# AT32UC3B1128 device description
Architecture: AVR32_UC3; Family: AVR UC3
Registers are 32-bit, read-write, reset 0x0 unless marked. A register's access mark holds for its fields unless they carry their own. Offsets are from the block's base; [hi:lo] are bit positions; {n}, {i} and the like mark numbered series; 'fields as' and 'values as' point back to an identical list.

## INTC — Interrupt Controller
Instances: INTC 0xFFFF0800
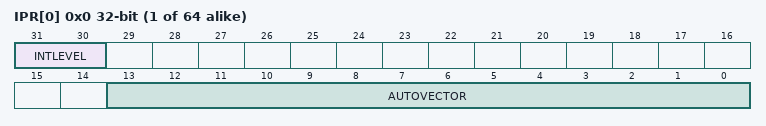
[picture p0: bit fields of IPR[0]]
{0x0+4i} IPR[{i}] (i=0..63) — Interrupt Priority Register
  [31:30] INTLEVEL — Interrupt Level
    {v}=INT{v} (v=0..3)
  [13:0] AUTOVECTOR — Handler offset
{0x100+4i} IRR[{i}] (i=0..63) ro — Interrupt Request Register
{0x200+4i} ICR[{i}] (i=0..3) ro — Interrupt Cause Register
  [5:0] CAUSE — Cause Group Number

## ADC — Analog to Digital Converter
Instances: ADC 0xffff3c00
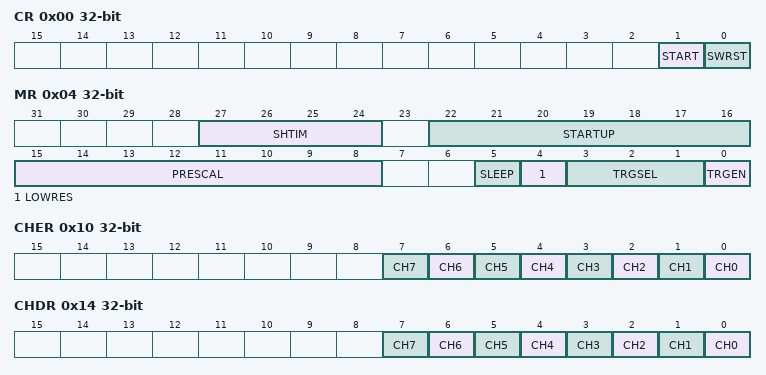
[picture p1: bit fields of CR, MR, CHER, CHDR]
0x00 CR wo reset not defined — Control Register
  [1] START — Start Conversion
  [0] SWRST — Software Reset
0x04 MR — Mode Register
  [27:24] SHTIM — Sample and Hold Time
  [22:16] STARTUP — Start Up Time
  [15:8] PRESCAL — Prescaler Rate Selection
  [5] SLEEP — Sleep Mode
  [4] LOWRES — Resolution
  [3:1] TRGSEL — Trigger Selection
  [0] TRGEN — Trigger Enable
0x10 CHER wo reset not defined — Channel Enable Register
  [n] CH{n} (n=0..7) — Channel {n} Enable
0x14 CHDR wo reset not defined — Channel Disable Register
  [n] CH{n} (n=0..7) — Channel {n} Disable
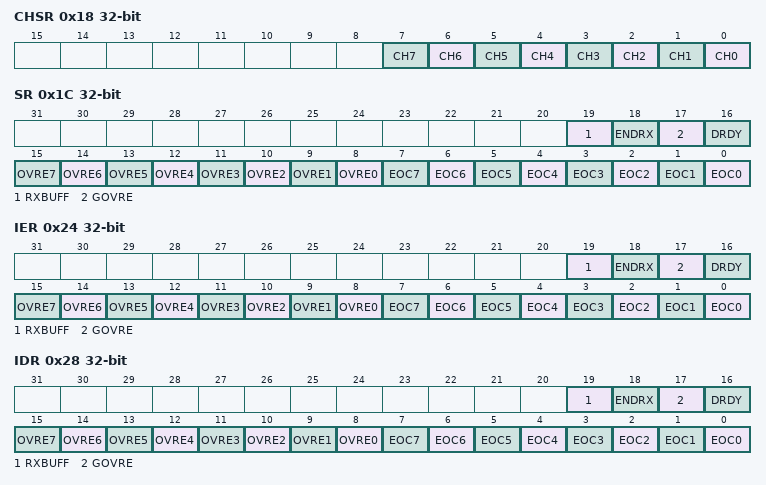
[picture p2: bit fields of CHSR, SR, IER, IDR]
0x18 CHSR ro — Channel Status Register
  [n] CH{n} (n=0..7)
0x1C SR ro reset not defined — Status Register
  [19] RXBUFF — RX Buffer Full
  [18] ENDRX — End of RX Buffer
  [17] GOVRE — General Overrun Error
  [16] DRDY — Data Ready
  [n+8] OVRE{n} (n=0..7) — Overrun Error {n}
  [n] EOC{n} (n=0..7) — End of Conversion {n}
0x20 LCDR ro reset not defined — Last Converted Data Register
  [9:0] LDATA — Last Data Converted
0x24 IER wo reset not defined — Interrupt Enable Register
  [19] RXBUFF — Receive Buffer Full Interrupt Enable
  [18] ENDRX — End of Receive Buffer Interrupt Enable
  [17] GOVRE — General Overrun Error Interrupt Enable
  [16] DRDY — Data Ready Interrupt Enable
  [n+8] OVRE{n} (n=0..7) — Overrun Error Interrupt Enable {n}
  [n] EOC{n} (n=0..7) — End of Conversion Interrupt Enable {n}
0x28 IDR wo reset not defined — Interrupt Disable Register
  [19] RXBUFF — Receive Buffer Full Interrupt Disable
  [18] ENDRX — End of Receive Buffer Interrupt Disable
  [17] GOVRE — General Overrun Interrupt Disable
  [16] DRDY — Data Ready Interrupt Disable
  [n+8] OVRE{n} (n=0..7) — Overrun Error Interrupt Disable {n}
  [n] EOC{n} (n=0..7) — End of Conversion Interrupt Disable {n}
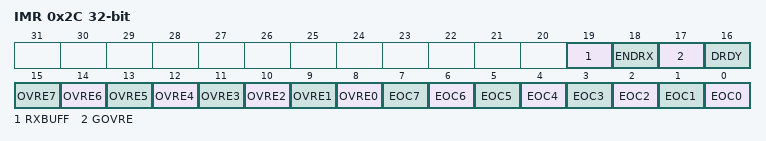
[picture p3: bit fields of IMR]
0x2C IMR ro — Interrupt Mask Register
  [19] RXBUFF — Receive Buffer Full Interrupt Mask
  [18] ENDRX — End of Receive Buffer Interrupt Mask
  [17] GOVRE — General Overrun Error Interrupt Mask
  [16] DRDY — Data Ready Interrupt Mask
  [n+8] OVRE{n} (n=0..7) — Overrun Error Interrupt Mask {n}
  [n] EOC{n} (n=0..7) — End of Conversion Interrupt Mask {n}
{0x30+4i} CDR{i} ro (i=0..7) — Channel Data Register {i}
  [9:0] DATA — Converted Data
0xFC VERSION ro reset not defined

## EIC — External Interrupt Controller
Instances: EIC 0xffff0d80
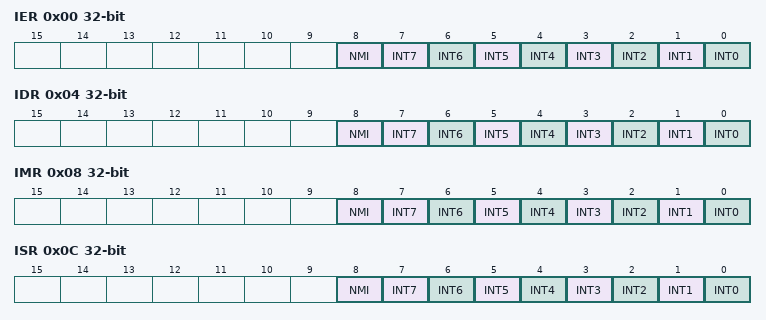
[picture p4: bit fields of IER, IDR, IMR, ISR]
0x00 IER wo — Interrupt Enable Register
  [8] NMI — External Non Maskable CPU interrupt
  [n] INT{n} (n=0..7) — External Interrupt {n}
0x04 IDR wo — Interrupt Disable Register
  fields as IER
0x08 IMR ro — Interrupt Mask Register
  fields as IER
0x0C ISR ro — Interrupt Status Register
  fields as IER
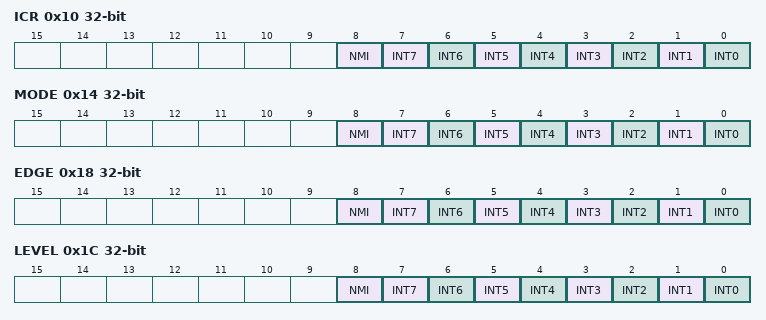
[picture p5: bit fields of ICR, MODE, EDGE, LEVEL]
0x10 ICR wo — Interrupt Clear Register
  fields as IER
0x14 MODE
  fields as IER
0x18 EDGE
  fields as IER
0x1C LEVEL
  fields as IER
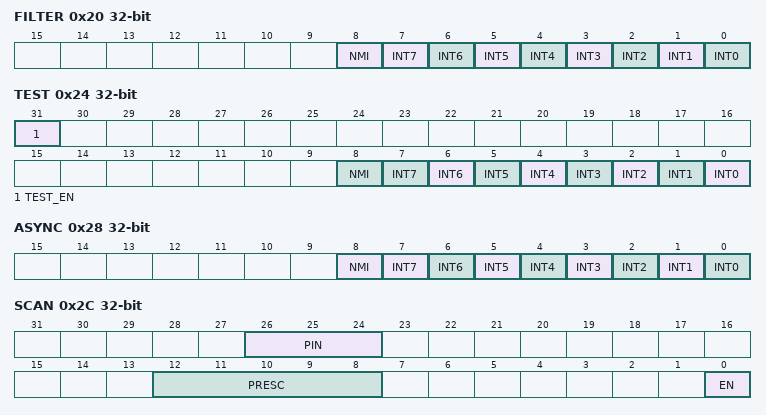
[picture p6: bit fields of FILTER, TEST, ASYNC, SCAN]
0x20 FILTER
  fields as IER
0x24 TEST
  [31] TEST_EN — Test Enable
  [8] NMI — External Non Maskable CPU interrupt
  [n] INT{n} (n=0..7) — External Interrupt {n}
0x28 ASYNC — Asynchronous Mode Register
  fields as IER
0x2C SCAN
  [26:24] PIN — SCAN Pin
  [12:8] PRESC — SCAN Prescale
  [0] EN — SCAN Enable
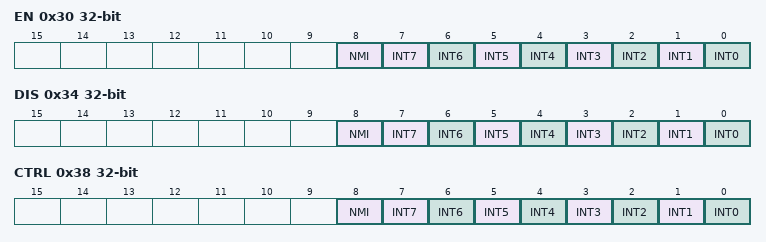
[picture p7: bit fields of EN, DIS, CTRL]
0x30 EN wo — Enable Register
  fields as IER
0x34 DIS wo — Disable Register
  fields as IER
0x38 CTRL — Control Register
  fields as IER

## FLASHC — Flash Controller
Instances: FLASHC 0xfffe1400
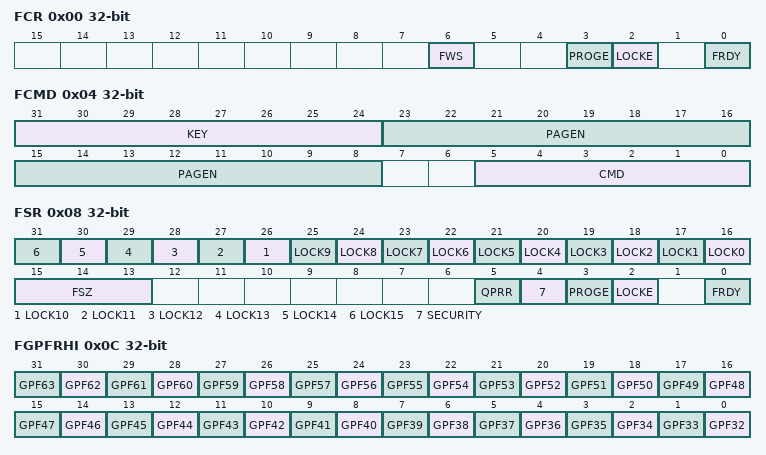
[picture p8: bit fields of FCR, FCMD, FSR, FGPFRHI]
0x00 FCR — Flash Controller Control Register
  [6] FWS, [3] PROGE, [2] LOCKE, [0] FRDY
0x04 FCMD — Flash Controller Command Register
  [31:24] KEY
    165=KEY
  [23:8] PAGEN
  [5:0] CMD — Command
    0=NOP; 1=WP; 2=EP; 3=CPB; 4=LP; 5=UP; 6=EA; 7=WGPB; 8=EGPB; 9=SSB; 10=PGPFB; 11=EAGPF; 12=QPR; 13=WUP; 14=EUP; 15=QPRUP
0x08 FSR reset not defined — Flash Controller Status Register
  [n+16] LOCK{n} (n=0..15)
  [15:13] FSZ
    0=32; 1=64; 2=128; 3=256; 4=384; 5=512; 6=768; 7=1024
  [5] QPRR
  [4] SECURITY
  [3] PROGE
  [2] LOCKE
  [0] FRDY
0x0C FGPFRHI ro reset not defined — Flash Controller General Purpose Fuse Register High
  [n-32] GPF{n} (n=32..63)
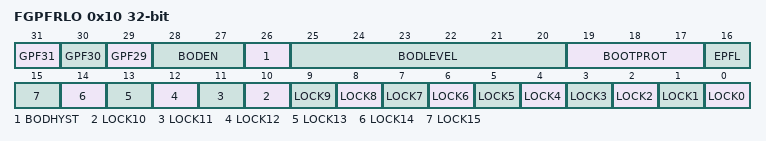
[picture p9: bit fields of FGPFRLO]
0x10 FGPFRLO ro reset not defined — Flash Controller General Purpose Fuse Register Low
  [31] GPF31, [30] GPF30, [29] GPF29, [28:27] BODEN, [26] BODHYST, [25:20] BODLEVEL, [19:17] BOOTPROT, [16] EPFL, [n] LOCK{n} (n=0..15)
